AUTOSAR XML (schema 4-2-2)
package /WdgM_SWC
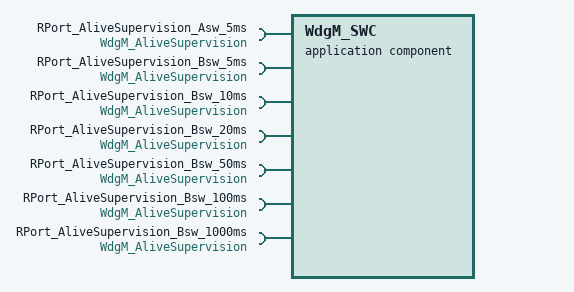
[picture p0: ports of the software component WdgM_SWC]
  application sw component type WdgM_SWC
    7 x require port, all with required-interface=WdgM_AliveSupervision:
      RPort_AliveSupervision_Asw_5ms
      RPort_AliveSupervision_Bsw_5ms
      RPort_AliveSupervision_Bsw_10ms
      RPort_AliveSupervision_Bsw_20ms
      RPort_AliveSupervision_Bsw_50ms
      RPort_AliveSupervision_Bsw_100ms
      RPort_AliveSupervision_Bsw_1000ms
    behavior IB_WdgM_SWC: data-type-mapping=WdgM_Type_Map
      7 x timing event:
        TimingEvent_0: start-on-event=WdgMSwc_CheckpointReached_Asw_5ms, period=0.005
        TimingEvent_1: start-on-event=WdgMSwc_CheckpointReached_Bsw_5ms, period=0.005
        TimingEvent_2: start-on-event=WdgMSwc_CheckpointReached_Bsw_10ms, period=0.01
        TimingEvent_3: start-on-event=WdgMSwc_CheckpointReached_Bsw_20ms, period=0.02
        TimingEvent_4: start-on-event=WdgMSwc_CheckpointReached_Bsw_50ms, period=0.05
        TimingEvent_5: start-on-event=WdgMSwc_CheckpointReached_Bsw_100ms, period=0.1
        TimingEvent_6: start-on-event=WdgMSwc_CheckpointReached_Bsw_1000ms, period=1.0
      7 x runnable:
        WdgMSwc_CheckpointReached_Asw_5ms: mode-access-points=[currentMode, currentMode]
          sync call SynchronousServerCallPoint_0: operation=RPort_AliveSupervision_Asw_5ms.CheckpointReached
        WdgMSwc_CheckpointReached_Bsw_5ms
          sync call SynchronousServerCallPoint_0: operation=RPort_AliveSupervision_Bsw_5ms.CheckpointReached
        WdgMSwc_CheckpointReached_Bsw_10ms
          sync call SynchronousServerCallPoint_0: operation=RPort_AliveSupervision_Bsw_10ms.CheckpointReached
        WdgMSwc_CheckpointReached_Bsw_20ms
          sync call SynchronousServerCallPoint_0: operation=RPort_AliveSupervision_Bsw_20ms.CheckpointReached
        WdgMSwc_CheckpointReached_Bsw_50ms
          sync call SynchronousServerCallPoint_0: operation=RPort_AliveSupervision_Bsw_50ms.CheckpointReached
        WdgMSwc_CheckpointReached_Bsw_100ms
          sync call SynchronousServerCallPoint_0: operation=RPort_AliveSupervision_Bsw_100ms.CheckpointReached
        WdgMSwc_CheckpointReached_Bsw_1000ms
          sync call SynchronousServerCallPoint_0: operation=RPort_AliveSupervision_Bsw_1000ms.CheckpointReached
